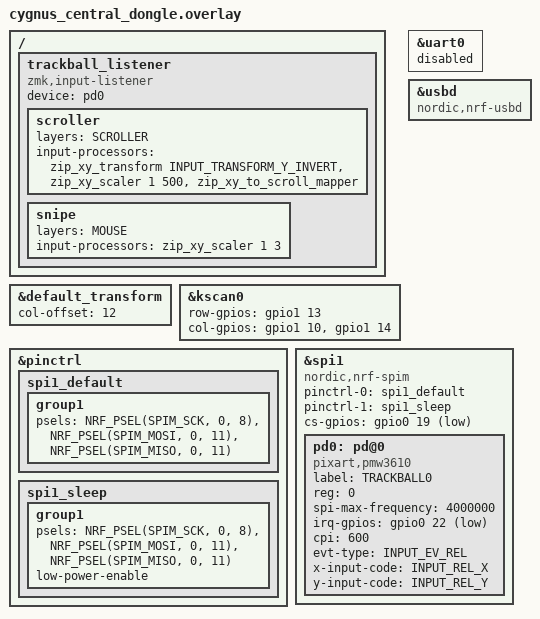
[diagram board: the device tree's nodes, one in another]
/*
 * Copyright (c) 2020 The ZMK Contributors
 *
 * SPDX-License-Identifier: MIT
 */
#include <zephyr/dt-bindings/input/input-event-codes.h>
#include <input/processors.dtsi>
#include <dt-bindings/zmk/input_transform.h>
#include "cygnus.dtsi"

#define SCROLLER 1
#define MOUSE 4

&default_transform {
	col-offset = <12>;
};

&kscan0 {
    row-gpios
	= <&gpio1 13 (GPIO_ACTIVE_HIGH | GPIO_PULL_DOWN)>
	;
    col-gpios
        = <&gpio1 10 GPIO_ACTIVE_HIGH>
        , <&gpio1 14 GPIO_ACTIVE_HIGH>
        ;
};

&pinctrl {
    spi1_default: spi1_default {
        group1 {
            psels = <NRF_PSEL(SPIM_SCK, 0, 8)>,
                <NRF_PSEL(SPIM_MOSI, 0, 11)>,
                <NRF_PSEL(SPIM_MISO, 0, 11)>;
        };
    };

    spi1_sleep: spi1_sleep {
        group1 {
            psels = <NRF_PSEL(SPIM_SCK, 0, 8)>,
                <NRF_PSEL(SPIM_MOSI, 0, 11)>,
                <NRF_PSEL(SPIM_MISO, 0, 11)>;
            low-power-enable;
        };
    };
};

&uart0 {
	status = "disabled";
};

zephyr_udc0: &usbd {
    compatible = "nordic,nrf-usbd";
    status = "okay";
};

&spi1 {
	compatible = "nordic,nrf-spim";
	status = "okay";
    pinctrl-0 = <&spi1_default>;
	pinctrl-1 = <&spi1_sleep>;
	pinctrl-names = "default", "sleep";
	cs-gpios = <&gpio0 19 GPIO_ACTIVE_LOW>;
	pd0: pd@0 {
		compatible = "pixart,pmw3610";
		status = "okay";
		label = "TRACKBALL0";
		reg = <0>;
		spi-max-frequency = <4000000>;
	    irq-gpios = <&gpio0 22 (GPIO_ACTIVE_LOW | GPIO_PULL_UP)>;
	    cpi = <600>;
	    evt-type = <INPUT_EV_REL>;
	    x-input-code = <INPUT_REL_X>;
	    y-input-code = <INPUT_REL_Y>;
	};
};

/ {
  trackball_listener: trackball_listener {
    compatible = "zmk,input-listener";
    status = "okay";
    device = <&pd0>;
    scroller {
        layers = <SCROLLER>;
        input-processors =
            <&zip_xy_transform INPUT_TRANSFORM_Y_INVERT>,
            <&zip_xy_scaler 1 500>,
            <&zip_xy_to_scroll_mapper>;
    };

    snipe {
        layers = <MOUSE>;
        input-processors = <&zip_xy_scaler 1 3>;
    };
  };
}; 
